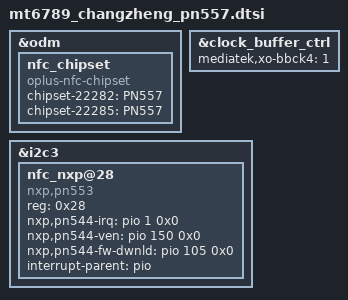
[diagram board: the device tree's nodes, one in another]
/**********************************************************************************
* Copyright (c)  2008-2020  Guangdong oplus Mobile Comm Corp., Ltd
*
***********************************************************************************/
&odm {
	nfc_chipset:nfc_chipset {
		compatible = "oplus-nfc-chipset";
		chipset-22282 = "PN557";
		chipset-22285 = "PN557";
	};
};

&clock_buffer_ctrl {
	mediatek,xo-bbck4 = <1>;
};

&i2c3 {
       status = "okay";
       nfc_nxp@28 {
               compatible = "nxp,pn553";
               reg = <0x28>;
               nxp,pn544-irq = <&pio 1 0x0>;
               nxp,pn544-ven = <&pio 150 0x0>;
               nxp,pn544-fw-dwnld = <&pio 105 0x0>;
               interrupt-parent = <&pio>;
       };
};
